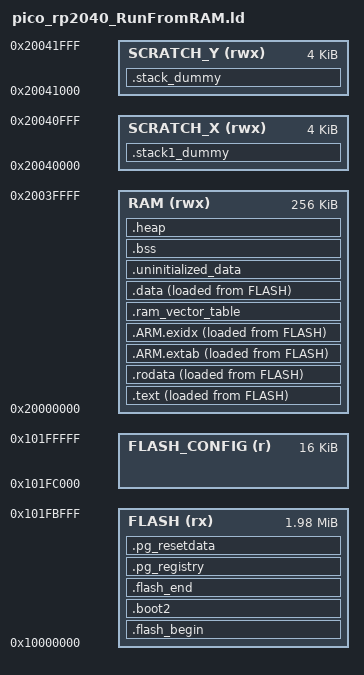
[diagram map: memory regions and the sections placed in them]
/* RP2040 Linker Script - Run from RAM
   Based on pico-sdk linker scripts for RP2040 (Cortex-M0+)
*/

MEMORY
{
    FLASH(rx) : ORIGIN = 0x10000000, LENGTH = 2032k
    FLASH_CONFIG(r) : ORIGIN = 0x101FC000, LENGTH = 16k
    RAM(rwx) : ORIGIN =  0x20000000, LENGTH = 256k
    SCRATCH_X(rwx) : ORIGIN = 0x20040000, LENGTH = 4k
    SCRATCH_Y(rwx) : ORIGIN = 0x20041000, LENGTH = 4k
}

ENTRY(_entry_point)

SECTIONS
{
    .flash_begin : {
        __flash_binary_start = .;
    } > FLASH

    .boot2 : {
        __boot2_start__ = .;
        KEEP (*(.boot2))
        __boot2_end__ = .;
    } > FLASH

    ASSERT(__boot2_end__ - __boot2_start__ == 256,
        "ERROR: Pico second stage bootloader must be 256 bytes in size")

    /* For copy to RAM: text and rodata stored in FLASH but executed/read from RAM */
    .text : {
        __logical_binary_start = .;
        KEEP (*(.vectors))
        KEEP (*(.binary_info_header))
        __binary_info_header_end = .;
        KEEP (*(.reset))
        *(.init)
        *(.text*)
        *(.fini)
        *crtbegin.o(.ctors)
        *crtbegin?.o(.ctors)
        *(EXCLUDE_FILE(*crtend?.o *crtend.o) .ctors)
        *(SORT(.ctors.*))
        *(.ctors)
        *crtbegin.o(.dtors)
        *crtbegin?.o(.dtors)
        *(EXCLUDE_FILE(*crtend?.o *crtend.o) .dtors)
        *(SORT(.dtors.*))
        *(.dtors)

        . = ALIGN(4);
        PROVIDE_HIDDEN (__preinit_array_start = .);
        KEEP(*(SORT(.preinit_array.*)))
        KEEP(*(.preinit_array))
        PROVIDE_HIDDEN (__preinit_array_end = .);

        . = ALIGN(4);
        PROVIDE_HIDDEN (__init_array_start = .);
        KEEP(*(SORT(.init_array.*)))
        KEEP(*(.init_array))
        PROVIDE_HIDDEN (__init_array_end = .);

        . = ALIGN(4);
        PROVIDE_HIDDEN (__fini_array_start = .);
        *(SORT(.fini_array.*))
        *(.fini_array)
        PROVIDE_HIDDEN (__fini_array_end = .);

        *(.eh_frame*)
        . = ALIGN(4);
    } > RAM AT> FLASH

    .rodata : {
        *(.rodata*)
        . = ALIGN(4);
        *(SORT_BY_ALIGNMENT(SORT_BY_NAME(.flashdata*)))
        . = ALIGN(4);
    } > RAM AT> FLASH

    .ARM.extab :
    {
        *(.ARM.extab* .gnu.linkonce.armextab.*)
    } > RAM AT> FLASH

    __exidx_start = .;
    .ARM.exidx :
    {
        *(.ARM.exidx* .gnu.linkonce.armexidx.*)
    } > RAM AT> FLASH
    __exidx_end = .;

    . = ALIGN(4);
    __etext = .;

    .ram_vector_table (NOLOAD): {
        *(.ram_vector_table)
    } > RAM

    .data : {
        __data_start__ = .;
        *(vtable)
        *(.time_critical*)
        . = ALIGN(4);
        *(.data*)
        . = ALIGN(4);
        *(.after_data.*)
        . = ALIGN(4);
        PROVIDE_HIDDEN (__mutex_array_start = .);
        KEEP(*(SORT(.mutex_array.*)))
        KEEP(*(.mutex_array))
        PROVIDE_HIDDEN (__mutex_array_end = .);
        . = ALIGN(4);
        *(.jcr)
        . = ALIGN(4);
        __data_end__ = .;
    } > RAM AT> FLASH

    .uninitialized_data (NOLOAD): {
        . = ALIGN(4);
        *(.uninitialized_data*)
    } > RAM

    .bss (NOLOAD) : {
        . = ALIGN(4);
        __bss_start__ = .;
        *(SORT_BY_ALIGNMENT(SORT_BY_NAME(.bss*)))
        *(COMMON)
        . = ALIGN(4);
        __bss_end__ = .;
    } > RAM

    .heap (NOLOAD):
    {
        __end__ = .;
        end = __end__;
        KEEP(*(.heap*))
        __HeapLimit = .;
    } > RAM

    .stack1_dummy (NOLOAD):
    {
        *(.stack1*)
    } > SCRATCH_X
    .stack_dummy (NOLOAD):
    {
        KEEP(*(.stack*))
    } > SCRATCH_Y

    .flash_end : {
        KEEP(*(.embedded_end_block*))
        PROVIDE(__flash_binary_end = .);
    } > FLASH

    __StackLimit = ORIGIN(RAM) + LENGTH(RAM);
    __StackOneTop = ORIGIN(SCRATCH_X) + LENGTH(SCRATCH_X);
    __StackTop = ORIGIN(SCRATCH_Y) + LENGTH(SCRATCH_Y);
    __StackOneBottom = __StackOneTop - SIZEOF(.stack1_dummy);
    __StackBottom = __StackTop - SIZEOF(.stack_dummy);
    PROVIDE(__stack = __StackTop);

    ASSERT(__StackLimit >= __HeapLimit, "region RAM overflowed")

    /* Betaflight config storage */
    .pg_registry : {
        PROVIDE_HIDDEN (__pg_registry_start = .);
        KEEP (*(.pg_registry))
        KEEP (*(SORT(.pg_registry.*)))
        PROVIDE_HIDDEN (__pg_registry_end = .);
    } > FLASH

    .pg_resetdata : {
        PROVIDE_HIDDEN (__pg_resetdata_start = .);
        KEEP (*(.pg_resetdata))
        PROVIDE_HIDDEN (__pg_resetdata_end = .);
    } > FLASH

    __config_start = ORIGIN(FLASH_CONFIG);
    __config_end = ORIGIN(FLASH_CONFIG) + LENGTH(FLASH_CONFIG);

    PROVIDE(__flash_config_start = __config_start);
    PROVIDE(__flash_config_end = __config_end);
}
